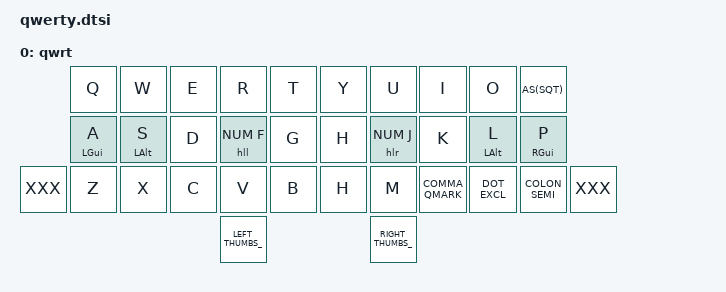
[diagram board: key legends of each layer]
/**
 * Alpha Layer - QWERTY
 */

/ {
	keymap {
		compatible = "zmk,keymap";

    	qwerty {
    		display-name = "qwrt";
      		bindings = <
//                ╭─────────────┬─────────────┬─────────────┬─────────────┬─────────────╮   ╭─────────────┬─────────────┬─────────────┬─────────────┬─────────────╮
                   &kp Q         &kp W         &kp E         &kp R         &kp T             &kp Y         &kp U         &kp I         &kp O         AS(SQT)
//                ├─────────────┼─────────────┼─────────────┼─────────────┼─────────────┤   ├─────────────├─────────────┼─────────────┼─────────────┼─────────────┤
                   &hml LGUI A   &hml LALT S   &kp D         &hll NUM F    &kp G             &kp H         &hlr NUM J    &kp K         &hmr LALT L   &hmr RGUI P
//  ╭─────────────┬─────────────┼─────────────┼─────────────┼─────────────┼─────────────┤   ├─────────────├─────────────┼─────────────┼─────────────┼─────────────┬─────────────╮
     XXX           &kp Z         &kp X         &kp C         &kp V         &kp B             &kp H         &kp M         COMMA_QMARK   DOT_EXCL      COLON_SEMI    XXX
//  ╰─────────────┴─────────────┴─────────────┼─────────────┼─────────────┼─────────────┤   ├─────────────├─────────────┼─────────────┼─────────────┴─────────────┴─────────────╯
                                                             _LEFT_THUMBS_                                _RIGHT_THUMBS_
//                                            ╰─────────────┴─────────────┴─────────────╯   ╰─────────────┴─────────────┴─────────────╯
      		>;
    	};
  	};
};
